# ESP32C5_RADIO register map
Vendor: Espressif; Series: ESP32-C5; File version: 0.1
Registers are 32-bit, read-write, no defined reset value unless marked. A register's access mark holds for its fields unless they carry their own. Offsets are from the block's base; [hi:lo] are bit positions; {n}, {i} and the like mark numbered series.

## IEEE802154_INTERRUPT_ROUTE — The CPU interrupt-matrix word for ESP32-C5 modem source 12 (ZB_MAC). This source-specific view is retained with the IEEE 802.15.4 owner and publishes only the generated field readers needed to prove that a polled or validation transaction starts with the CPU route detached.
Base 0x60010030
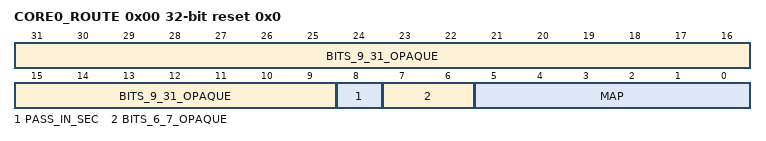
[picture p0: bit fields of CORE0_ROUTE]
0x00 CORE0_ROUTE reset 0x0 — Project-assigned name. Destination and security routing for ZB_MAC.
  [31:9] BITS_9_31_OPAQUE — Opaque: meaning not established. Bits the vendor declares reserved, retained solely so reset-state observation cannot erase an unexpected nonzero value.
  [8] PASS_IN_SEC — Project-assigned name. Secure-world pass-through selection for the peripheral source.
  [7:6] BITS_6_7_OPAQUE — Opaque: meaning not established. Bits the vendor declares reserved, retained solely so reset-state observation cannot erase an unexpected nonzero value.
  [5:0] MAP — Project-assigned name. CPU-interrupt destination selected for the peripheral source.

## MODEM_ETM — ESP32-C5 modem event-task matrix at MODEM_BASE + 0x8800. The public IEEE 802.15.4 driver names the channel-enable, set and clear words and the per-channel event/task pair at an eight-byte stride from 0x18, and programs channels zero and one. Other channels and identifiers remain absent and no reset values are claimed.
Base 0x600A8800
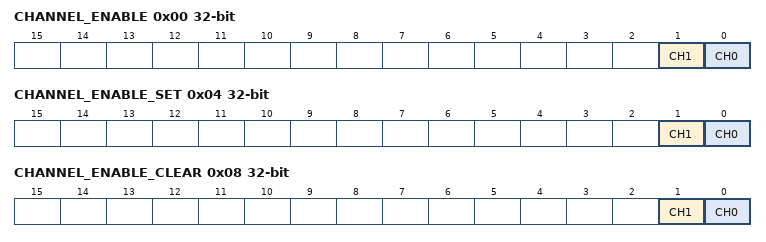
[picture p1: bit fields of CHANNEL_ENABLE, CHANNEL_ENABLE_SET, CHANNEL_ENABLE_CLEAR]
0x00 CHANNEL_ENABLE ro — Project-assigned name. Channel-enable status word. The IEEE 802.15.4 driver reads it to decide whether a channel must be disabled.
  [1] CH1 — Project-assigned name. Enabled state of channel 1.
  [0] CH0 — Project-assigned name. Enabled state of channel 0.
0x04 CHANNEL_ENABLE_SET — Project-assigned name. Channel-enable set word. The IEEE 802.15.4 driver reads it and writes it back with the selected channel bit added; the effect of writing other bits is not reviewed.
  [1] CH1 — Project-assigned name. Enable request of channel 1.
  [0] CH0 — Project-assigned name. Enable request of channel 0.
0x08 CHANNEL_ENABLE_CLEAR — Project-assigned name. Channel-enable clear word. The IEEE 802.15.4 driver reads it and writes it back with the selected channel bit added, only when that channel is enabled.
  [1] CH1 — Project-assigned name. Disable request of channel 1.
  [0] CH0 — Project-assigned name. Disable request of channel 0.
{0x18+8i} CH{i}_EVENT (i=0..1) — Project-assigned name. Complete event identifier monitored by the selected channel.
  [31:0] ID — Project-assigned name. Event identifier written as a complete word.
    58=IEEE802154_TIMER1_OVERFLOW; 59=IEEE802154_TIMER0_OVERFLOW
{0x1C+8i} CH{i}_TASK (i=0..1) — Project-assigned name. Complete task identifier triggered when the selected channel's event occurs.
  [31:0] ID — Project-assigned name. Task identifier written as a complete word.
    65=IEEE802154_ED_TRIG_TX; 66=IEEE802154_RX_START; 69=IEEE802154_TX_START

## MODEM_SYSCON_RADIO — ESP32-C5 MODEM_SYSCON clock gates and resets at MODEM_BASE + 0x9C00 driven by the vendor modem clock devices of the IEEE 802.15.4 module (802154_MAC, BT_I154_COMMON_BB, ETM, BT_APB) and its MAC reset. Other fields remain absent and are preserved by every field transaction.
Base 0x600A9C00
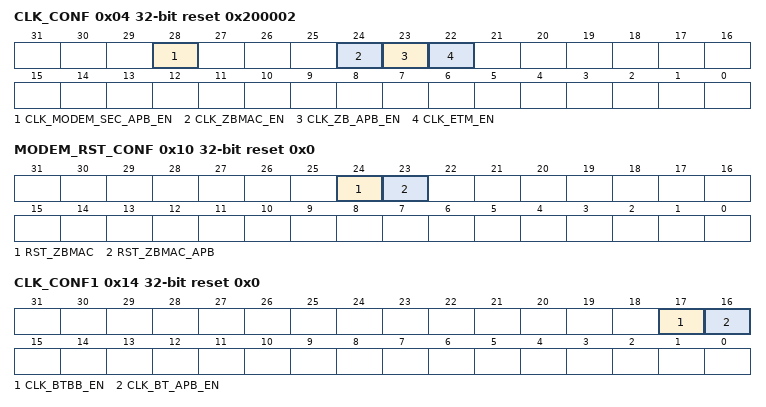
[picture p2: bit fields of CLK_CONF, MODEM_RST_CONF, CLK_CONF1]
0x04 CLK_CONF reset 0x200002 — Modem clock selectors and protocol clock gates.
  [28] CLK_MODEM_SEC_APB_EN — Enable the modem-security APB clock.
  [24] CLK_ZBMAC_EN — Enable the IEEE 802.15.4 MAC clock.
  [23] CLK_ZB_APB_EN — Enable the IEEE 802.15.4 APB clock.
  [22] CLK_ETM_EN — Enable the modem ETM clock.
0x10 MODEM_RST_CONF reset 0x0 — Modem protocol reset lines.
  [24] RST_ZBMAC — Hold the IEEE 802.15.4 MAC in reset.
  [23] RST_ZBMAC_APB — Hold the IEEE 802.15.4 APB interface in reset.
0x14 CLK_CONF1 reset 0x0 — Wi-Fi, front-end and Bluetooth clock gates.
  [17] CLK_BTBB_EN — Enable the baseband clock shared by Bluetooth LE and IEEE 802.15.4.
  [16] CLK_BT_APB_EN — Enable the Bluetooth APB clock.
